AUTOSAR XML (schema 4-3-0)
package /MICROSAR/CddNpmGen2_swc/ComponentTypes
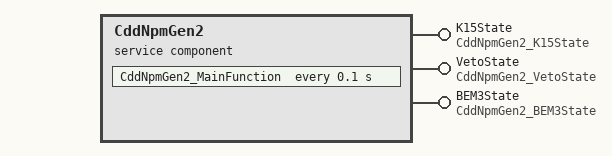
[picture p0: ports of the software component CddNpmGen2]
  service sw component type CddNpmGen2: category=SERVICE_COMPONENT
    provide port K15State: provided-interface=CddNpmGen2_K15State
    provide port VetoState: provided-interface=CddNpmGen2_VetoState
    provide port BEM3State: provided-interface=CddNpmGen2_BEM3State
    behavior CddNpmGen2InternalBehavior: handle-termination-and-restart=NO-SUPPORT
      timing event Timer_CddNpmGen2_MainFunction: start-on-event=CddNpmGen2_MainFunction, period=0.1
      operation invoked event OpEventSetK15State_SetK15State_K15State: start-on-event=SetK15State, operation=K15State.SetK15State
      operation invoked event OpEventSetVetoState_SetVetoState_VetoState: start-on-event=SetVetoState, operation=VetoState.SetVetoState
      operation invoked event OpEventSetBEM3State_SetBEM3State_BEM3State: start-on-event=SetBEM3State, operation=BEM3State.SetBEM3State
      port-api-options:
        enable-take-address=true, indirect-api=false, port=K15State
        enable-take-address=true, indirect-api=false, port=VetoState
        enable-take-address=true, indirect-api=false, port=BEM3State
      4 x runnable:
        CddNpmGen2_MainFunction
        SetK15State: can-be-invoked-concurrently=true, symbol=CddNpmGen2_SetK15State
        SetVetoState: can-be-invoked-concurrently=true, symbol=CddNpmGen2_SetVetoState
        SetBEM3State: can-be-invoked-concurrently=true, symbol=CddNpmGen2_SetBEM3State
  swc implementation CddNpmGen2Implementation: programming-language=C, behavior=CddNpmGen2InternalBehavior
package /MICROSAR/CddNpmGen2_swc/Interfaces
  client server interface CddNpmGen2_K15State: is-service=true, service-kind=VENDOR-SPECIFIC
    operation SetK15State: possible-error=CddNpmGen2_K15State/E_NOT_OK
      arg state: type=boolean, direction=IN
    error E_NOT_OK: error-code=1
  client server interface CddNpmGen2_VetoState: is-service=true, service-kind=VENDOR-SPECIFIC
    operation SetVetoState: possible-error=CddNpmGen2_VetoState/E_NOT_OK
      arg stateECUVeto: type=boolean, direction=IN
      arg stateBusVeto: type=boolean, direction=IN
    error E_NOT_OK: error-code=1
  client server interface CddNpmGen2_BEM3State: is-service=true, service-kind=VENDOR-SPECIFIC
    operation SetBEM3State: possible-error=CddNpmGen2_BEM3State/E_NOT_OK
      arg state: type=boolean, direction=IN
    error E_NOT_OK: error-code=1
